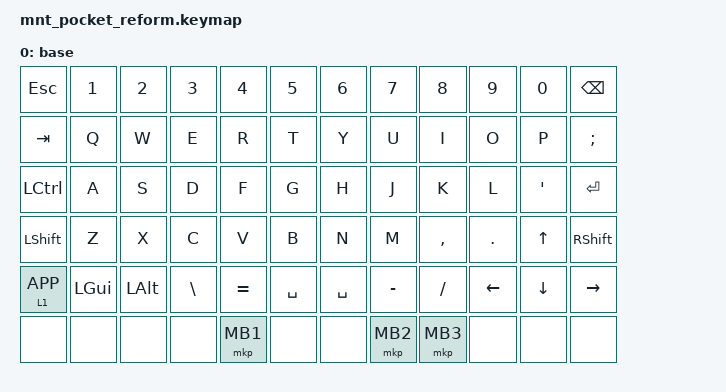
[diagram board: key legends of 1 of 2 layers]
#include <behaviors.dtsi>
#include <dt-bindings/zmk/mouse.h>

/ {
    combos {
        compatible = "zmk,combos";

        combo_mb3 {
            bindings = <&mkp MB3>;
            key-positions = <64 67>;
        };
    };

    behaviors {
        td_bootloader: td_bootloader {
            compatible = "zmk,behavior-tap-dance";
            bindings = <&none>, <&bootloader>;
            label = "TD_BOOTLOADER";
            #binding-cells = <0>;
        };
    };

    keymap {
        compatible = "zmk,keymap";

        base {
            bindings = <
                &kp ESC     &kp N1    &kp N2    &kp N3    &kp N4    &kp N5         &kp N6         &kp N7    &kp N8    &kp N9    &kp N0    &kp BSPC
                &kp TAB     &kp Q     &kp W     &kp E     &kp R     &kp T          &kp Y          &kp U     &kp I     &kp O     &kp P     &kp SEMI
                &kp LCTRL   &kp A     &kp S     &kp D     &kp F     &kp G          &kp H          &kp J     &kp K     &kp L     &kp SQT   &kp RET
                &kp LSHFT   &kp Z     &kp X     &kp C     &kp V     &kp B          &kp N          &kp M     &kp COMMA &kp DOT   &kp UP    &kp RSHFT
                &lt 1 K_APP &kp LGUI  &kp LALT  &kp BSLH  &kp EQUAL &kp SPACE      &kp SPACE      &kp MINUS &kp SLASH &kp LEFT  &kp DOWN  &kp RIGHT
                &none       &none     &none     &none     &mkp MB1  &none          &none          &mkp MB2  &mkp MB3  &none     &none     &none
            >;
        };

        fn {
            bindings = <
                &kp GRAVE   &kp F1    &kp F2    &kp F3    &kp F4    &kp F5         &kp F6         &kp F7    &kp F8    &kp F9    &kp F10   &kp DEL
                &kp TAB     &kp F11   &kp F12   &kp F13   &kp R     &kp T          &kp Y          &kp U     &kp I     &kp LBKT  &kp RBKT  &kp SEMI
                &trans      &trans    &trans    &trans    &trans    &trans         &trans         &trans    &trans    &trans    &trans    &trans
                &kp LSHFT   &kp Z     &kp X     &kp C     &kp V     &kp B          &kp N          &kp M     &kp COMMA &kp DOT   &kp PG_UP &kp RSHFT
                &kp K_APP   &kp RGUI  &kp RALT  &kp BSLH  &kp EQUAL &td_bootloader &td_bootloader &kp MINUS &kp SLASH &kp HOME  &kp PG_DN &kp END
            >;
        };
    };
};
